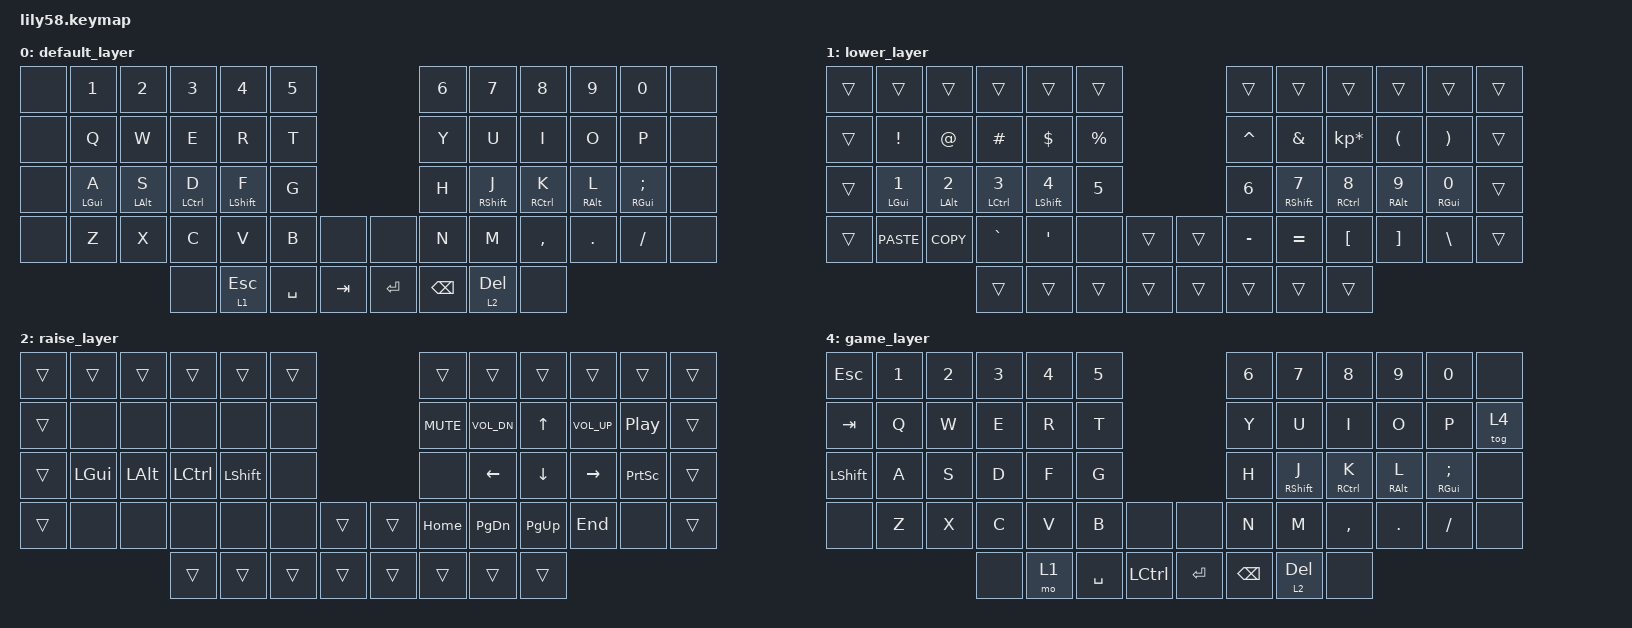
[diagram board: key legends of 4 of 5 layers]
/*
 * Copyright (c) 2020 The ZMK Contributors
 *
 * SPDX-License-Identifier: MIT
 */

#include <behaviors.dtsi>
#include <dt-bindings/zmk/keys.h>
#include <dt-bindings/zmk/bt.h>

//#define KC_COPY &kp LC(C)
//#define KC_PASTE &kp LC(V)

#define DEFAULT 0
#define LOWER   1
#define RAISE   2
#define ADJUST  3
#define GAME    4

&mt {
	tapping-term-ms = <200>;
	flavor = "tap-preferred";
};

/ {

	conditional_layers {
		compatible = "zmk,conditional-layers";
		tri_layer {
			if-layers = <1 2>;
			then-layer = <3>;
		};
	};
	
	keymap {
		compatible = "zmk,keymap";

		default_layer {
			bindings = <
&none &kp N1     &kp N2     &kp N3       &kp N4       &kp N5                    &kp N6   &kp N7       &kp N8      &kp N9     &kp N0        &none
&none &kp Q      &kp W      &kp E        &kp R        &kp T                     &kp Y    &kp U        &kp I       &kp O      &kp P         &none
&none &mt LGUI A &mt LALT S &mt LCTRL D  &mt LSHIFT F &kp G                     &kp H    &mt RSHIFT J &mt RCTRL K &mt RALT L &mt RGUI SEMI &none
&none &kp Z      &kp X      &kp C        &kp V        &kp B     &none   &none   &kp N    &kp M        &kp COMMA   &kp DOT    &kp FSLH      &none
                            &none        &lt 1 ESC    &kp SPACE &kp TAB &kp RET &kp BSPC &lt 2 DEL    &none
			>;
		};

		lower_layer {
			bindings = <
&trans &trans      &trans      &trans       &trans        &trans                  &trans    &trans        &trans          &trans      &trans      &trans
&trans &kp EXCL    &kp AT      &kp HASH     &kp DOLLAR    &kp PRCNT               &kp CARET &kp AMPS      &kp KP_MULTIPLY &kp LPAR    &kp RPAR    &trans
&trans &mt LGUI N1 &mt LALT N2 &mt LCTRL N3 &mt LSHIFT N4 &kp N5                  &kp N6    &mt RSHIFT N7 &mt RCTRL N8    &mt RALT N9 &mt RGUI N0 &trans
&trans &kp K_PASTE &kp K_COPY  &kp GRAVE    &kp APOS      &none     &trans &trans &kp MINUS &kp EQUAL     &kp LBKT        &kp RBKT    &kp BSLH    &trans
                               &trans       &trans        &trans    &trans &trans &trans    &trans        &trans
			>;
		};

		raise_layer {
			bindings = <
&trans &trans   &trans   &trans    &trans     &trans               &trans     &trans       &trans    &trans       &trans    &trans
&trans &none    &none    &none     &none      &none                &kp C_MUTE &kp C_VOL_DN &kp UP    &kp C_VOL_UP &kp C_PP  &trans
&trans &kp LGUI &kp LALT &kp LCTRL &kp LSHIFT &none                &none      &kp LEFT     &kp DOWN  &kp RIGHT    &kp PSCRN &trans
&trans &none    &none    &none     &none      &none  &trans &trans &kp HOME   &kp PG_DN    &kp PG_UP &kp END      &none     &trans
                         &trans    &trans     &trans &trans &trans &trans     &trans       &trans
			>;
		};
		
		adjust_layer {
			bindings = <
&trans &trans      &trans       &trans       &trans        &trans               &trans &trans        &trans       &trans      &trans       &trans
&trans &bt BT_CLR  &bt BT_SEL 0 &bt BT_SEL 1 &bt BT_SEL 2  &none         		&none  &none         &none        &none       &none        &tog 4
&trans &mt LGUI F1 &mt LALT F2  &mt LCTRL F3 &mt LSHIFT F4 &kp F5               &kp F6 &mt RSHIFT F7 &mt RCTRL F8 &mt RALT F9 &mt RGUI F10 &trans
&trans &kp F11     &kp F12      &none        &none         &none  &trans &trans &none  &none         &none        &none       &none        &trans
                                &trans       &trans        &trans &trans &trans &trans &trans        &trans       &trans
			>;
		};
		
		game_layer {
			bindings = <
&kp ESC    &kp N1 &kp N2 &kp N3 &kp N4 &kp N5                      &kp N6   &kp N7       &kp N8      &kp N9     &kp N0        &none
&kp TAB    &kp Q  &kp W  &kp E  &kp R  &kp T                       &kp Y    &kp U        &kp I       &kp O      &kp P         &tog 4
&kp LSHIFT &kp A  &kp S  &kp D  &kp F  &kp G                       &kp H    &mt RSHIFT J &mt RCTRL K &mt RALT L &mt RGUI SEMI &none
&none      &kp Z  &kp X  &kp C  &kp V  &kp B     &none     &none   &kp N    &kp M        &kp COMMA   &kp DOT    &kp FSLH      &none
                         &none  &mo 1  &kp SPACE &kp LCTRL &kp RET &kp BSPC &lt 2 DEL    &none
			>;
		};
	};
};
